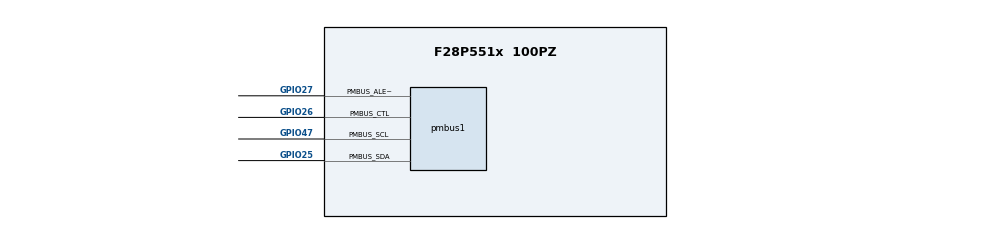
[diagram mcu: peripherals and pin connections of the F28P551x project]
/**
 * @cliArgs --device "F28P551x" --part "F28P551x_100PZ" --package "100PZ" --product "C2000WARE@6.02.00.00_EA1"
 * @versions {"tool":"1.25.999+297"}
 */

/**
 * Import the modules used in this configuration.
 */
const device_support = scripting.addModule("/driverlib/device_support.js");
const pmbus          = scripting.addModule("/driverlib/pmbus.js", {}, false);
const pmbus1         = pmbus.addInstance();
const sysctl         = scripting.addModule("/driverlib/sysctl.js");
const CMD            = scripting.addModule("/utilities/cmd_tool/cmd_syscfg/source/CMD", {}, false);
const CMD1           = CMD.addInstance();

/**
 * Write custom configuration values to the imported modules.
 */
pmbus1.$name                        = "myPMBUS0";
pmbus1.useInterrupts                = true;
pmbus1.registerInterrupts           = true;
pmbus1.enabledInterrupts            = ["PMBUS_INT_ALERT","PMBUS_INT_DATA_READY","PMBUS_INT_DATA_REQUEST","PMBUS_INT_EOM","PMBUS_INT_TARGET_ADDR_READY"];
pmbus1.pmbus.$assign                = "PMBUSA";
pmbus1.pmbus.pmbus_alertPin.$assign = "GPIO27";
pmbus1.pmbus.pmbus_ctlPin.$assign   = "GPIO26";
pmbus1.pmbus.pmbus_sclPin.$assign   = "GPIO47";
pmbus1.pmbus.pmbus_sdaPin.$assign   = "GPIO25";
pmbus1.BaudRate                   = 9000000;
pmbus1.useInterrupts              = true;
pmbus1.sclQual.padConfig          = "PULLUP";
pmbus1.sdaQual.padConfig          = "PULLUP";
pmbus1.PMBusInt.interruptHandler    = "pmbusIntHandler";
pmbus1.PMBusInt.enableInterrupt     = true;

sysctl.enable_SYSCTL_PERIPH_CLK_CLA1  = false;
sysctl.enable_SYSCTL_PERIPH_CLK_DMA   = false;
sysctl.enable_SYSCTL_PERIPH_CLK_HRCAL = false;

CMD1.$name = "CMD0"; 
